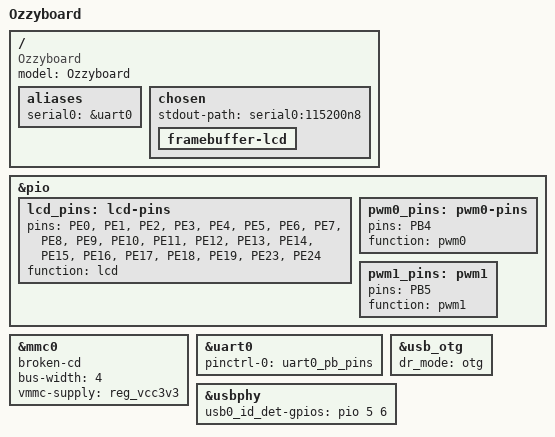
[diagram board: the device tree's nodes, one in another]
/dts-v1/;
#include "sun8i-V3s-Ozzyboard_uboot.dtsi"
#include "sunxi-common-regulators.dtsi"

/ {
	model = "Ozzyboard";
	compatible = "Ozzyboard", "allwinner,sun8i-v3s";

	aliases {
		serial0 = &uart0;
	};

	chosen {
		stdout-path = "serial0:115200n8";
		
		framebuffer-lcd {			
			status = "okay";
		};
	};		
};

&pio {
	lcd_pins: lcd-pins {
		pins = "PE0", "PE1", "PE2", "PE3", "PE4", "PE5",
		       "PE6", "PE7", "PE8", "PE9", "PE10", "PE11",
		       "PE12", "PE13", "PE14", "PE15", "PE16", "PE17",
		       "PE18", "PE19", "PE23", "PE24";
		function = "lcd";
	};

	pwm0_pins: pwm0-pins {
		pins = "PB4";
		function = "pwm0";
	};
	
	pwm1_pins: pwm1 {
		pins = "PB5";
		function = "pwm1";
	};
};


&mmc0 {
	broken-cd;
	bus-width = <4>;
	vmmc-supply = <&reg_vcc3v3>;
	status = "okay";
};

&uart0 {
	pinctrl-0 = <&uart0_pb_pins>;
	pinctrl-names = "default";
	status = "okay";
};

&usb_otg {
	dr_mode = "otg";
	status = "okay";
};

&usbphy {
	usb0_id_det-gpios = <&pio 5 6 GPIO_ACTIVE_HIGH>;
	status = "okay";
};
